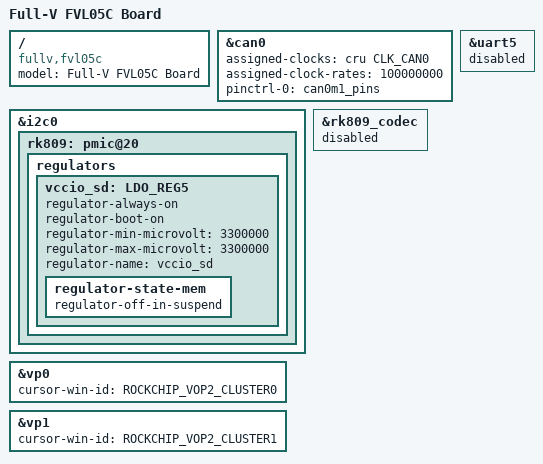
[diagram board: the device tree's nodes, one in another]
// SPDX-License-Identifier: (GPL-2.0+ OR MIT)
/*
 * Copyright (c) 2020 Rockchip Electronics Co., Ltd.
 *
 */

#include "rk3568-rklaser1.dtsi"
#include "rk3568-rklaser1-linux.dtsi"
#include <dt-bindings/display/rockchip_vop.h>

/ {
        model = "Full-V FVL05C Board";
        compatible = "fullv,fvl05c", "rockchip,rk3568";
};

&can0 {
        assigned-clocks = <&cru CLK_CAN0>;
        assigned-clock-rates = <100000000>;
        pinctrl-names = "default";
        pinctrl-0 = <&can0m1_pins>;
        status = "okay";
};

&i2c0 {
        rk809: pmic@20 {
		regulators {
			vccio_sd: LDO_REG5 {
				regulator-always-on;
				regulator-boot-on;
				regulator-min-microvolt = <3300000>;
				regulator-max-microvolt = <3300000>;
				regulator-name = "vccio_sd";
				regulator-state-mem {
					regulator-off-in-suspend;
				};
			};
                };
        };
};

&rk809_codec {
        status = "disabled";
};

&uart5 {
        status = "disabled";
};

&vp0 {
	cursor-win-id = <ROCKCHIP_VOP2_CLUSTER0>;
};

&vp1 {
	cursor-win-id = <ROCKCHIP_VOP2_CLUSTER1>;
};
